# atl_ATL_MMR_0FEE0000h register map
Vendor: Texas Instruments
Peripheral module from a debugger description file (folder AM275x).
Registers are 32-bit, read-write, reset 0x0 unless marked. A register's access mark holds for its fields unless they carry their own. Offsets are as the file gives them; lines under a group give offsets from that group; [hi:lo] are bit positions; {n}, {i} and the like mark numbered series; 'fields as' and 'values as' point back to an identical list; <NAME> marks a mode.

## atl_mmr
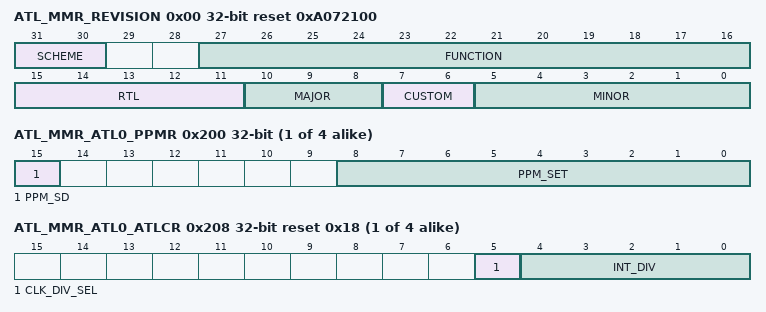
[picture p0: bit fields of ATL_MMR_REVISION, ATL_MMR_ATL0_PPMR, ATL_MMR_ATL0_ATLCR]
0x00 ATL_MMR_REVISION ro reset 0xA072100 — The Revision Register contains the major and minor revisions for the module.
  [31:30] SCHEME — PID register scheme Reset Source: mod_g_rst_n
  [27:16] FUNCTION — Module ID Reset Source: mod_g_rst_n
  [15:11] RTL — RTL revision. Will vary depending on release. Reset Source: mod_g_rst_n
  [10:8] MAJOR — Major revision Reset Source: mod_g_rst_n
  [7:6] CUSTOM — Custom Reset Source: mod_g_rst_n
  [5:0] MINOR — Minor revision Reset Source: mod_g_rst_n
{0x200+0x80*i} ATL_MMR_ATL{i}_PPMR (i=0..3) — The PPM register is used by the Audio re-timing code. The DAC over-sampling clock will slow down or speed up by the PPM written to bits [8:0].
  [15] PPM_SD — 1 = Slow down 0 = Speed up Reset Source: mod_g_rst_n
  [8:0] PPM_SET — This is the 9-bit parts-per-million value in the adjusting circuit. PPM adjustment = PPMSET/2^20 Reset Source: mod_g_rst_n
{0x204+0x80*i} ATL_MMR_ATL{i}_BBSR ro (i=0..3) — The measuring circuit produces a 16-bit Sample Count. Its inputs are the Audio IIS Word Select (AWS) and the Baseband IIS Word Select (BWS) from their respective MCASP pins. The sample count is a read-only register.
  [15:0] SMP_CNT — This is the 16-bit sample count from the measuring circuit Reset Source: mod_g_rst_n
{0x208+0x80*i} ATL_MMR_ATL{i}_ATLCR reset 0x18 (i=0..3) — The modem Clock Divide Select bit is used during factory calibration of the radio to match latency between the analog and digital signal paths. The ATL Internal Divider divides down the ATL master clock to make ATCLK.
  [5] CLK_DIV_SEL — 0: MODCLK = AWS divided by 2^16 1: MODCLK = AWS divided by 2^12 Reset Source: mod_g_rst_n
  [4:0] INT_DIV — Sets ratio of ATLPCLK to ATCLK Reset Source: mod_g_rst_n
{0x210+0x80*i} ATL_MMR_ATL{i}_SWEN (i=0..3) — The software enable register is used to enable/disable the ATL.
  [0] ENABLE — When disabled the ATL registers are forced to known states for simulation purposes. Runtime startup doesn't require initial values because measurement is relative to an arbitrary initial value. All registers are reset to zero except ATLCR.INT_DIV which is resets to 24 (divide-by-25, because zero is not a legal divide ratio.) Reset Source: mod_g_rst_n
{0x214+0x80*i} ATL_MMR_ATL{i}_BWSMUX (i=0..3) — The Baseband IIS Word Select mux select control register
  [3:0] SELECT — BWS input select: 0000: atl_io_port_bws[0] 0001: atl_io_port_bws[1] 0010: atl_io_port_bws[2] 0011: atl_io_port_bws[3] 0100: atl_io_port_bws[4] 0101: atl_io_port_bws[5] 0110: atl_io_port_bws[6] 0111: atl_io_port_bws[7] 1000: atl_io_port_bws[8] 1001: atl_io_port_bws[9] 1010: atl_io_port_bws[10] 1011: atl_io_port_bws[11] 1100: atl_io_port_bws[12] 1101: atl_io_port_bws[13] 1110: atl_io_port_bws[14] 1111: atl_io_port_bws[15] Reset Source: mod_g_rst_n
{0x218+0x80*i} ATL_MMR_ATL{i}_AWSMUX (i=0..3) — The Audio IIS Word Select mux select control register
  [3:0] SELECT — AWS input select: 0000: atl_io_port_aws[0] 0001: atl_io_port_aws[1] 0010: atl_io_port_aws[2] 0011: atl_io_port_aws[3] 0100: atl_io_port_aws[4] 0101: atl_io_port_aws[5] 0110: atl_io_port_aws[6] 0111: atl_io_port_aws[7] 1000: atl_io_port_aws[8] 1001: atl_io_port_aws[9] 1010: atl_io_port_aws[10] 1011: atl_io_port_aws[11] 1100: atl_io_port_aws[12] 1101: atl_io_port_aws[13] 1110: atl_io_port_aws[14] 1111: atl_io_port_aws[15] Reset Source: mod_g_rst_n
0x21C ATL_MMR_ATL0_PCLKMUX — ATL core input clock mux select control register
  [0] SELECT — ATL[0-3] core clock select: 0: vbus_clk 1: atl_clk Reset Source: mod_g_rst_n
{0x21C+0x80*i} ATL_MMR_ATL{i}_PCLKMUX (i=1..3) — ATL core input clock mux select control register
  [0] SELECT — Non-functional Reset Source: mod_g_rst_n
